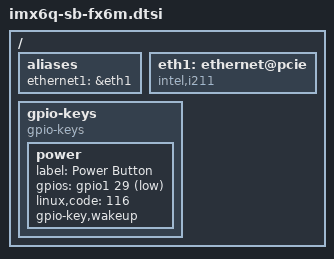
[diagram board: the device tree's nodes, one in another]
/*
 * Copyright 2014 CompuLab Ltd.
 *
 * Author: Valentin Raevsky <valentin@compulab.co.il>
 *
 * The code contained herein is licensed under the GNU General Public
 * License. You may obtain a copy of the GNU General Public License
 * Version 2 or later at the following locations:
 *
 * http://www.opensource.org/licenses/gpl-license.html
 * http://www.gnu.org/copyleft/gpl.html
 */

#include "imx6q-sb-fx6x.dtsi"

/ {
	aliases {
		ethernet1 = &eth1;
	};

	eth1: ethernet@pcie {
		compatible = "intel,i211";
		status = "okay";
        };

	gpio-keys {
		compatible = "gpio-keys";
		power {
			label = "Power Button";
			gpios = <&gpio1 29 1>;
			linux,code = <116>; /* KEY_POWER */
			gpio-key,wakeup;
		};
	};
};
